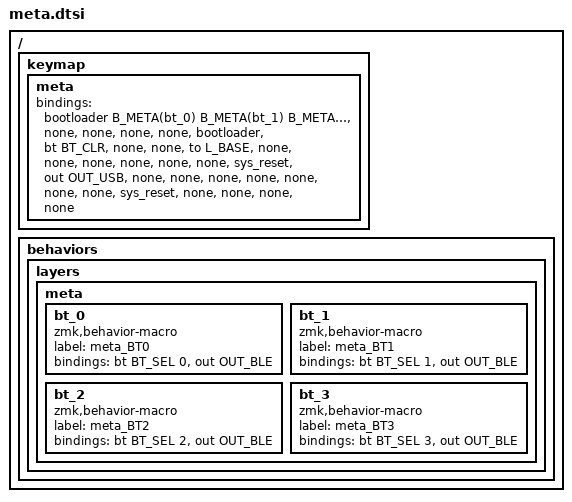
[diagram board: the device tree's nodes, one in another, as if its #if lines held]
// Copyright (c) 2022 The ZMK Contributors
// SPDX-License-Identifier: MIT

#include <dt-bindings/zmk/bt.h>
#include <dt-bindings/zmk/outputs.h>

#define B_META(key) B_LAYER(meta, key)

/ {
    keymap {
        meta {
            bindings = <
        // ╭──────────────┬──────────────┬──────────────┬──────────────┬──────────────╮   ╭──────────────┬──────────────┬──────────────┬──────────────┬──────────────╮
        // │  BOOT        │  BT 0        │  BT 1        │  BT 2        │  BT 3        │   │              │              │              │              │  BOOT        │
             &bootloader    B_META(bt_0)   B_META(bt_1)   B_META(bt_2)   B_META(bt_3)       &none          &none          &none          &none          &bootloader
        // ├──────────────┼──────────────┼──────────────┼──────────────┼──────────────┤   ├──────────────┼──────────────┼──────────────┼──────────────┼──────────────┤
        // │  BT CLEAR    │              │              │  BASE        │              │   │              │              │              │              │              │
             &bt BT_CLR     &none          &none          &to L_BASE     &none              &none          &none          &none          &none          &none
        // ├──────────────┼──────────────┼──────────────┼──────────────┼──────────────┤   ├──────────────┼──────────────┼──────────────┼──────────────┼──────────────┤
        // │  RESET       │  USB OUTPUT  │              │              │              │   │              │              │              │              │  RESET       │
             &sys_reset     &out OUT_USB   &none          &none          &none              &none          &none          &none          &none          &sys_reset
        // ╰──────────────┴──────────────┴──────────────┼──────────────┼──────────────┤   ├──────────────┼──────────────┼──────────────┴──────────────┴──────────────╯
#ifdef KEY_34
        //                                              ╭──────────────┬──────────────╮   ╭──────────────┬──────────────╮
        //                                              |              |              |   |              |              |
                                                          &none          &none              &none          &none
        //                                              ╰──────────────┴──────────────╯   ╰──────────────┴──────────────╯
#else
        //                               ╭──────────────┬──────────────┬──────────────╮   ╭──────────────┬──────────────┬──────────────╮
        //                               |              |              |              |   |              |              |              |
                                           &none          &none          &none              &none          &none          &none
        //                               ╰──────────────┴──────────────┴──────────────╯   ╰──────────────┴──────────────┴──────────────╯
#endif
            >;
        };
    };

    behaviors {
        layers {
            meta {
                bt_0 {
                    compatible = "zmk,behavior-macro";
                    label = "meta_BT0";
                    #binding-cells = <0>;
                    bindings = <&bt BT_SEL 0>, <&out OUT_BLE>;
                };

                bt_1 {
                    compatible = "zmk,behavior-macro";
                    label = "meta_BT1";
                    #binding-cells = <0>;
                    bindings = <&bt BT_SEL 1>, <&out OUT_BLE>;
                };

                bt_2 {
                    compatible = "zmk,behavior-macro";
                    label = "meta_BT2";
                    #binding-cells = <0>;
                    bindings = <&bt BT_SEL 2>, <&out OUT_BLE>;
                };

                bt_3 {
                    compatible = "zmk,behavior-macro";
                    label = "meta_BT3";
                    #binding-cells = <0>;
                    bindings = <&bt BT_SEL 3>, <&out OUT_BLE>;
                };
            };
        };
    };
};
